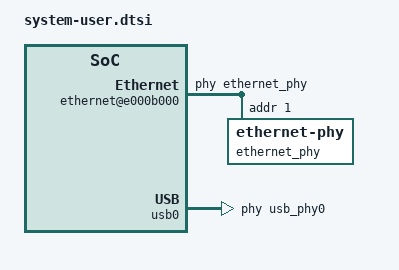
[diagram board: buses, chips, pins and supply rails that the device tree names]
/include/ "system-conf.dtsi"
/ {
	amba {

		ethernet@e000b000 {
			phy-handle = <&ethernet_phy>;
			ethernet_phy: ethernet-phy@1{
				reg = <1>;
			};
		};
	};
        usb_phy0: phy0 {
                compatible = "ulpi-phy";
                #phy-cells = <0>;
                reg = <0xe0002000 0x1000>;
                view-port = <0x170>;
                drv-vbus;
        };
};

&usb0 {
        usb-phy = <&usb_phy0>;
};

&flash0 {
        compatible = "jedec,spi-nor";
        reg = <0x0>;
        spi-tx-bus-width = <1>;
        spi-rx-bus-width = <4>;
        spi-max-frequency = <100000000>;
};
